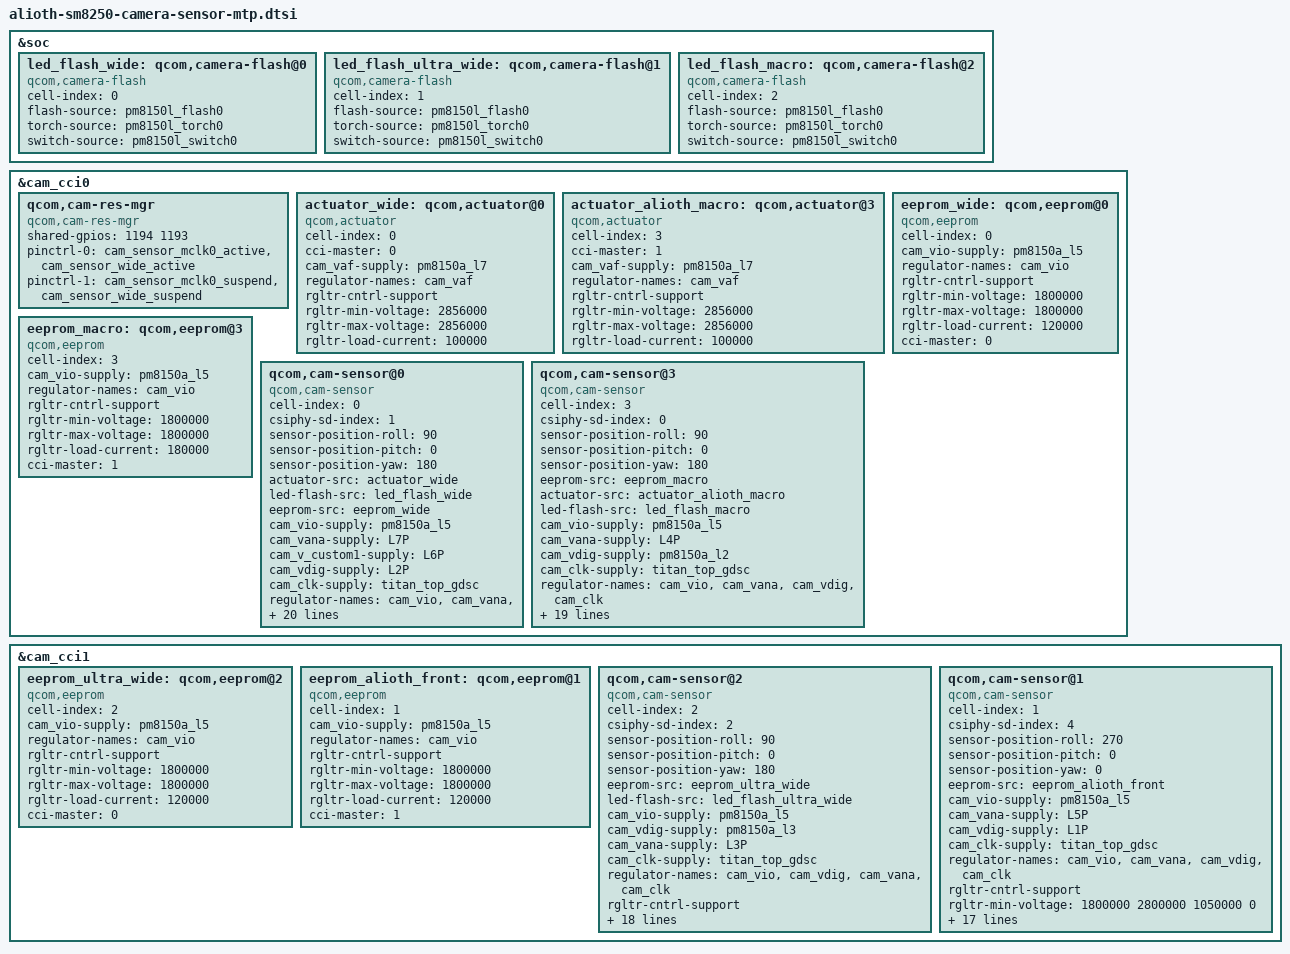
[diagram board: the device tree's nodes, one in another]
#include "alioth-sm8250-camera-board.dtsi"

&soc {
	led_flash_wide: qcom,camera-flash@0 {
		cell-index = <0>;
		compatible = "qcom,camera-flash";
		flash-source = <&pm8150l_flash0>;
		torch-source = <&pm8150l_torch0>;
		switch-source = <&pm8150l_switch0>;
		status = "ok";
	};
	led_flash_ultra_wide: qcom,camera-flash@1 {
		cell-index = <1>;
		compatible = "qcom,camera-flash";
		flash-source = <&pm8150l_flash0>;
		torch-source = <&pm8150l_torch0>;
		switch-source = <&pm8150l_switch0>;
		status = "ok";
	};

	led_flash_macro: qcom,camera-flash@2 {
		cell-index = <2>;
		compatible = "qcom,camera-flash";
		flash-source = <&pm8150l_flash0>;
		torch-source = <&pm8150l_torch0>;
		switch-source = <&pm8150l_switch0>;
		status = "ok";
	};
};

&cam_cci0 {
	qcom,cam-res-mgr {
		compatible = "qcom,cam-res-mgr";
		status = "ok";
		shared-gpios = <1194 1193>;
		pinctrl-names = "cam_res_mgr_default", "cam_res_mgr_suspend";
		pinctrl-0 = <&cam_sensor_mclk0_active
					&cam_sensor_wide_active>;
		pinctrl-1 = <&cam_sensor_mclk0_suspend
					&cam_sensor_wide_suspend>;
	};
	/* ALIOTH Wide actuator */
	actuator_wide: qcom,actuator@0 {
		cell-index = <0>;
		compatible = "qcom,actuator";
		cci-master = <0>;
		cam_vaf-supply = <&pm8150a_l7>;
		regulator-names = "cam_vaf";
		rgltr-cntrl-support;
		rgltr-min-voltage = <2856000>;
		rgltr-max-voltage = <2856000>;
		rgltr-load-current = <100000>;
	};
	/* ALIOTH macro actuator */
	actuator_alioth_macro: qcom,actuator@3 {
		cell-index = <3>;
		compatible = "qcom,actuator";
		cci-master = <1>;
		cam_vaf-supply = <&pm8150a_l7>;
		regulator-names = "cam_vaf";
		rgltr-cntrl-support;
		rgltr-min-voltage = <2856000>;
		rgltr-max-voltage = <2856000>;
		rgltr-load-current = <100000>;
	};
	/* ALIOTH Wide eeprom */
	eeprom_wide: qcom,eeprom@0 {
		cell-index = <0>;
		compatible = "qcom,eeprom";
		cam_vio-supply = <&pm8150a_l5>;
		regulator-names = "cam_vio";
		rgltr-cntrl-support;
		rgltr-min-voltage = <1800000>;
		rgltr-max-voltage = <1800000>;
		rgltr-load-current = <120000>;
		cci-master = <0>;
		status = "ok";
	};
	/* ALIOTH Macro eeprom */
	eeprom_macro: qcom,eeprom@3 {
		cell-index = <3>;
		compatible = "qcom,eeprom";
		cam_vio-supply = <&pm8150a_l5>;
		regulator-names = "cam_vio";
		rgltr-cntrl-support;
		rgltr-min-voltage = <1800000>;
		rgltr-max-voltage = <1800000>;
		rgltr-load-current = <180000>;
		cci-master = <1>;
		status = "ok";
	};

	/* ALIOTH Wide sensor   */
	qcom,cam-sensor@0 {
		cell-index = <0>;
		compatible = "qcom,cam-sensor";
		csiphy-sd-index = <1>;
		sensor-position-roll = <90>;
		sensor-position-pitch = <0>;
		sensor-position-yaw = <180>;
		actuator-src = <&actuator_wide>;
		led-flash-src = <&led_flash_wide>;
		eeprom-src = <&eeprom_wide>;
		cam_vio-supply = <&pm8150a_l5>;
		cam_vana-supply = <&L7P>;//AVDD2.9
		cam_v_custom1-supply =<&L6P>;//AVDD1.8
		cam_vdig-supply = <&L2P>;
		cam_clk-supply = <&titan_top_gdsc>;
		regulator-names = "cam_vio", "cam_vana", "cam_v_custom1", "cam_vdig",
			"cam_clk";
		rgltr-cntrl-support;
		rgltr-min-voltage = <1800000 2900000 1800000 1100000 0>;
		rgltr-max-voltage = <1800000 2900000 1800000 1100000 0>;
		rgltr-load-current = <120000 180000 80000 1200000 0>;
		gpio-no-mux = <0>;
		gpios = <&tlmm 94 0>,
				<&tlmm 93 0>;
		gpio-reset = <1>;
		gpio-req-tbl-num = <0 1>;
		gpio-req-tbl-flags = <1 0>;
		gpio-req-tbl-label = "CAMIF_MCLK0",
							"CAM_RESET0";
		sensor-mode = <0>;
		cci-master = <0>;
		status = "ok";
		use-shared-clk;
		clocks = <&clock_camcc CAM_CC_MCLK0_CLK>;
		clock-names = "cam_clk";
		clock-cntl-level = "turbo";
		clock-rates = <19200000>;
	};
	/* ALIOTH Macro sensor  */
	qcom,cam-sensor@3 {
		cell-index = <3>;
		compatible = "qcom,cam-sensor";
		csiphy-sd-index = <0>;
		sensor-position-roll = <90>;
		sensor-position-pitch = <0>;
		sensor-position-yaw = <180>;
		eeprom-src = <&eeprom_macro>;
		actuator-src = <&actuator_alioth_macro>;
		led-flash-src = <&led_flash_macro>;
		cam_vio-supply = <&pm8150a_l5>;
		cam_vana-supply = <&L4P>;
		cam_vdig-supply = <&pm8150a_l2>;
		cam_clk-supply = <&titan_top_gdsc>;
		regulator-names = "cam_vio","cam_vana", "cam_vdig",
			"cam_clk";
		rgltr-cntrl-support;
		rgltr-min-voltage = <1800000 2800000 1200000 0>;
		rgltr-max-voltage = <1800000 2800000 1200000 0>;
		rgltr-load-current = <180000 120000 120000 0>;
		gpio-no-mux = <0>;
		pinctrl-names = "cam_default", "cam_suspend";
		pinctrl-0 = <&cam_sensor_mclk1_active
				&cam_sensor_macro_active>;
		pinctrl-1 = <&cam_sensor_mclk1_suspend
				&cam_sensor_macro_suspend>;
		gpios = <&tlmm 95 0>,
			<&tlmm 92 0>;
		gpio-reset = <1>;
		gpio-req-tbl-num = <0 1>;
		gpio-req-tbl-flags = <1 0>;
		gpio-req-tbl-label = "CAMIF_MCLK1",
					"CAM_RESET1";
		sensor-mode = <0>;
		cci-master = <1>;
		status = "ok";
		clocks = <&clock_camcc CAM_CC_MCLK1_CLK>;
		clock-names = "cam_clk";
		clock-cntl-level = "turbo";
		clock-rates = <19200000>;
	};
};

&cam_cci1 {
	/* ALIOTH ULTRA_WIDE eeprom */
	eeprom_ultra_wide: qcom,eeprom@2 {
		cell-index = <2>;
		compatible = "qcom,eeprom";
		cam_vio-supply = <&pm8150a_l5>;
		regulator-names = "cam_vio";
		rgltr-cntrl-support;
		rgltr-min-voltage = <1800000>;
		rgltr-max-voltage = <1800000>;
		rgltr-load-current = <120000>;
		cci-master = <0>;
		status = "ok";
	};
	/* ALIOTH front eeprom */
	eeprom_alioth_front: qcom,eeprom@1 {
		cell-index = <1>;
		compatible = "qcom,eeprom";
		cam_vio-supply = <&pm8150a_l5>;
		regulator-names = "cam_vio";
		rgltr-cntrl-support;
		rgltr-min-voltage = <1800000>;
		rgltr-max-voltage = <1800000>;
		rgltr-load-current = <120000>;
		cci-master = <1>;
		status = "ok";
	};
	/* ALIOTH Ultra Wide sensor */
	qcom,cam-sensor@2 {
		cell-index = <2>;
		compatible = "qcom,cam-sensor";
		csiphy-sd-index = <2>;
		sensor-position-roll = <90>;
		sensor-position-pitch = <0>;
		sensor-position-yaw = <180>;
		eeprom-src = <&eeprom_ultra_wide>;
		led-flash-src = <&led_flash_ultra_wide>;
		cam_vio-supply = <&pm8150a_l5>;
		cam_vdig-supply = <&pm8150a_l3>;
		cam_vana-supply = <&L3P>;
		cam_clk-supply = <&titan_top_gdsc>;
		regulator-names = "cam_vio", "cam_vdig", "cam_vana", "cam_clk";
		rgltr-cntrl-support;
		rgltr-min-voltage = <1800000 1200000 2700000 0>;
		rgltr-max-voltage = <1800000 1200000 2700000 0>;
		rgltr-load-current = <120000 120000 120000 0>;
		gpio-no-mux = <0>;
		pinctrl-names = "cam_default", "cam_suspend";
		pinctrl-0 = <&cam_sensor_mclk2_active
			     &cam_sensor_rear_ultra_active>;
		pinctrl-1 = <&cam_sensor_mclk2_suspend
			     &cam_sensor_rear_ultra_suspend>;
		gpios = <&tlmm 96 0>,
				<&tlmm 78 0>;
		gpio-reset = <1>;
		gpio-req-tbl-num = <0 1>;
		gpio-req-tbl-flags = <1 0>;
		gpio-req-tbl-label = "CAMIF_MCLK2",
					"CAM_RESET2";
		sensor-mode = <0>;
		cci-master = <0>;
		status = "ok";
		clocks = <&clock_camcc CAM_CC_MCLK2_CLK>;
		clock-names = "cam_clk";
		clock-cntl-level = "turbo";
		clock-rates = <19200000>;
	};
	/* ALIOTH Front  */
	qcom,cam-sensor@1 {
		cell-index = <1>;
		compatible = "qcom,cam-sensor";
		csiphy-sd-index = <4>;
		sensor-position-roll = <270>;
		sensor-position-pitch = <0>;
		sensor-position-yaw = <0>;
		eeprom-src = <&eeprom_alioth_front>;
		cam_vio-supply = <&pm8150a_l5>;
		cam_vana-supply = <&L5P>;
		cam_vdig-supply = <&L1P>;
		cam_clk-supply = <&titan_top_gdsc>;
		regulator-names = "cam_vio", "cam_vana", "cam_vdig", "cam_clk";
		rgltr-cntrl-support;
		rgltr-min-voltage = <1800000 2800000 1050000 0>;
		rgltr-max-voltage = <1800000 2800000 1050000 0>;
		rgltr-load-current = <120000 120000 120000 0>;
		gpio-no-mux = <0>;
		pinctrl-names = "cam_default", "cam_suspend";
		pinctrl-0 = <&cam_sensor_mclk3_active
				     &cam_sensor_front_active>;
		pinctrl-1 = <&cam_sensor_mclk3_suspend
				     &cam_sensor_front_suspend>;
		gpios = <&tlmm 97 0>,
			    <&tlmm 109 0>;
		gpio-reset = <1>;
		gpio-req-tbl-num = <0 1>;
		gpio-req-tbl-flags = <1 0>;
		gpio-req-tbl-label = "CAMIF_MCLK3",
					"CAM_RESET3";
		sensor-mode = <0>;
		cci-master = <1>;
		status = "ok";
		clocks = <&clock_camcc CAM_CC_MCLK3_CLK>;
		clock-names = "cam_clk";
		clock-cntl-level = "turbo";
		clock-rates = <19200000>;
	};
};

